# RT584ZCM33 register map
Series: ARMv8-M Mainline; File version: 1.0
CPU: CM33 r0p0, little endian, MPU, no FPU, VTOR, 3 interrupt priority bits
Registers are 32-bit, read-write, reset 0x0 unless marked. A register's access mark holds for its fields unless they carry their own. Offsets are from the block's base; [hi:lo] are bit positions.

## BOD_COMP_Non-Secure — BOD_COMP Non-Secure Register block
Base 0x4001D000
Same registers: BOD_COMP_Secure 0x5001D000
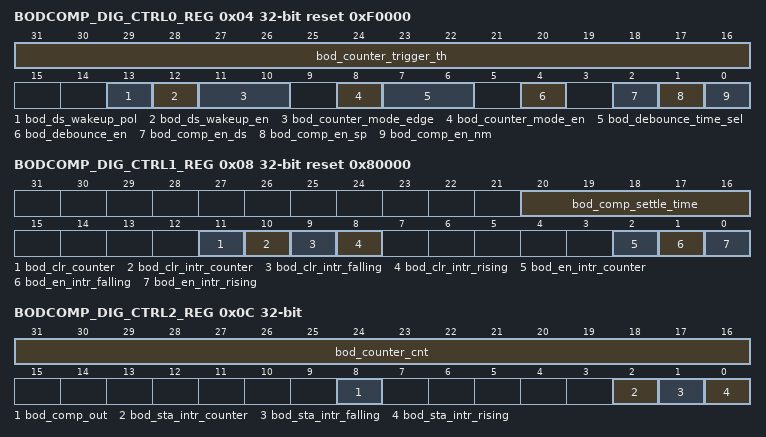
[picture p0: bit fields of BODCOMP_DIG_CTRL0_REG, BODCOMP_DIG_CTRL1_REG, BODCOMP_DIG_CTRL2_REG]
0x04 BODCOMP_DIG_CTRL0_REG reset 0xF0000 — bodcomp dig ctrl0
  [31:16] bod_counter_trigger_th — Set the trigger threshold of the counter mode. When comp_trigger_cnt > aux_comp_trigger_count , Interrupt will be triggered.
  [13] bod_ds_wakeup_pol — Set the wakeup polarity in Deepsleep when ds_wakeup_en is enabled. 0: level low 1: level high
    0=B_13_ITEM0 (level low); 1=B_13_ITEM1 (level high)
  [12] bod_ds_wakeup_en — Enable wakeup in Deepsleep when slow clock is disabled. 0: Disable deepsleep wakeup. 1: Enable deepsleep wakeup.
    0=B_12_ITEM0 (Disable deepsleep wakeup.); 1=B_12_ITEM1 (Enable deepsleep wakeup.)
  [11:10] bod_counter_mode_edge — Set the trigger polarity of Counter Mode 0: rising edge 1: falling edge 2: both edge
    0=B_10_to_11 (Set the trigger polarity of Counter Mode 0: rising edge 1: falling edge 2: both edge)
  [8] bod_counter_mode_en — Enable counter mode. When counter mode is enabled, every comparator event will let the counter count up until it reaches the trigger count. If counter mode will be used in Deepsleep, slow clock must be also enabled. 0: Disabled. 1: Enabled.
    0=B_8_ITEM0 (Disabled.); 1=B_8_ITEM1 (Enabled.)
  [7:6] bod_debounce_time_sel — Debounce time selection. 0: 2 slow clock 1: 4 slow clock 2: 8 slow clock
    0=B_6_to_7 (Debounce time selection. 0: 2 slow clock 1: 4 slow clock 2: 8 slow clock)
  [4] bod_debounce_en — Enable debounce. 0: Disable debounce 1: Enable debounce
    0=B_4_ITEM0 (Disable debounce); 1=B_4_ITEM1 (Enable debounce)
  [2] bod_comp_en_ds — Enable BOD Comparator in Deepsleep Mode. 0: disable 1: enable
    0=B_2_ITEM0 (disable); 1=B_2_ITEM1 (enable)
  [1] bod_comp_en_sp — Enable BOD Comparator in Sleep Mode. 0: disable 1: enable
    0=B_1_ITEM0 (disable); 1=B_1_ITEM1 (enable)
  [0] bod_comp_en_nm — Enable BOD Comparator in Normal Mode. 0: disable 1: enable
    0=B_0_ITEM0 (disable); 1=B_0_ITEM1 (enable)
0x08 BODCOMP_DIG_CTRL1_REG reset 0x80000 — bodcomp dig ctrl1
  [20:16] bod_comp_settle_time — Set the BOD comparator settle time in RCO32K cycles.
    0=B_16_to_20 (Set the BOD comparator settle time in RCO32K cycles.)
  [11] bod_clr_counter wo — Write 1 to clear the counter value.
    0=B_11 (Write 1 to clear the counter value.)
  [10] bod_clr_intr_counter wo — Write 1 to clear counter-triggered interrupt status
    0=B_10 (Write 1 to clear counter-triggered interrupt status)
  [9] bod_clr_intr_falling wo — Write 1 to clear falling-edge interrupt status
    0=B_9 (Write 1 to clear falling-edge interrupt status)
  [8] bod_clr_intr_rising wo — Write 1 to clear rising-edge interrupt status
    0=B_8 (Write 1 to clear rising-edge interrupt status)
  [2] bod_en_intr_counter — Counter trigger interrupt enable 0: disable 1: enable
    0=B_2_ITEM0 (disable); 1=B_2_ITEM1 (enable)
  [1] bod_en_intr_falling — Falling edge interrupt enable 0: disable 1: enable
    0=B_1_ITEM0 (disable); 1=B_1_ITEM1 (enable)
  [0] bod_en_intr_rising — Rising edge interrupt enable 0: disable 1: enable
    0=B_0_ITEM0 (disable); 1=B_0_ITEM1 (enable)
0x0C BODCOMP_DIG_CTRL2_REG ro — bodcomp dig ctrl2
  [31:16] bod_counter_cnt — The counter value. Be aware to set en_latch_counter before reading this value.
  [8] bod_comp_out — comp output
    0=B_8 (comp output)
  [2] bod_sta_intr_counter — Counter interrupt status 0: No interrupt 1: Interrupt pending
    0=B_2_ITEM0 (No interrupt); 1=B_2_ITEM1 (Interrupt pending)
  [1] bod_sta_intr_falling — Falling edge interrupt status 0: No interrupt 1: Interrupt pending
    0=B_1_ITEM0 (No interrupt); 1=B_1_ITEM1 (Interrupt pending)
  [0] bod_sta_intr_rising — Rising edge interrupt status 0: No interrupt 1: Interrupt pending
    0=B_0_ITEM0 (No interrupt); 1=B_0_ITEM1 (Interrupt pending)
